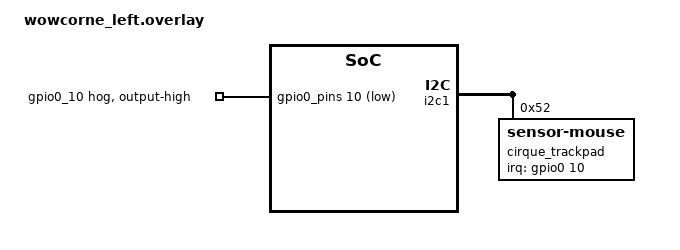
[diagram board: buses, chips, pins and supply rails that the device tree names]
/*
 * Copyright (c) 2020 Pete Johanson
 *
 * SPDX-License-Identifier: MIT
 */

#include "wowcorne.dtsi"

&kscan0 {
    col-gpios
        = <&pro_micro 21 GPIO_ACTIVE_HIGH>
        , <&pro_micro 20 GPIO_ACTIVE_HIGH>
        , <&pro_micro 19 GPIO_ACTIVE_HIGH>
        , <&pro_micro 18 GPIO_ACTIVE_HIGH>
        , <&pro_micro 15 GPIO_ACTIVE_HIGH>
        , <&pro_micro 14 GPIO_ACTIVE_HIGH>
        ;
};

&i2c1 {
    status = "okay";
    cirque_trackpad: cirque@52 {
        compatible = "cirque,trackpad";
        reg = <0x52>;
        interrupt-parent = <&gpio0>;
        interrupts = <10 0x4>;  // IRQ_TYPE_EDGE_FALLING 을 0x4로 바꿈
    };
};

&gpio0 {
    status = "okay";
    pinctrl-0 = <&gpio0_pins>;
    pinctrl-names = "default";
};

&gpio0_pins {
    gpio0_10: gpio0_10 {
        pinctrl-0 = <&gpio0_10>;
    };
};

&gpio0_10 {
    gpio-hog;
    gpios = <10 GPIO_ACTIVE_LOW>;
    output-high;
};

&cirque_trackpad {
    compatible = "zmk,sensor-mouse";
    status = "okay";
    mode = "relative";
    edge_scroll = <1>;
};
